# CTRL_MODULE_CORE register map
Vendor: Texas Instruments
Registers are 32-bit, access per field, reset 0x0 unless marked. A register's access mark holds for its fields unless they carry their own. Offsets are as the file gives them; [hi:lo] are bit positions; {n}, {i} and the like mark numbered series; 'fields as' and 'values as' point back to an identical list.

## CTRL_MODULE_CORE (part 5 of 11)
0xE78 CTRL_CORE_SRCOMP_SOUTH_SIDE ro — This register is related to the USB2_PHY2.
  [14:12] USB2PHY_CHG_DET_STATUS — Status of charger detection 0x0: Wait state 0x1: No contact 0x2: PS/2 0x3: Unknown error 0x4: Dedicated charger 0x5: HOST charger 0x6: PC 0x7: Interrupt
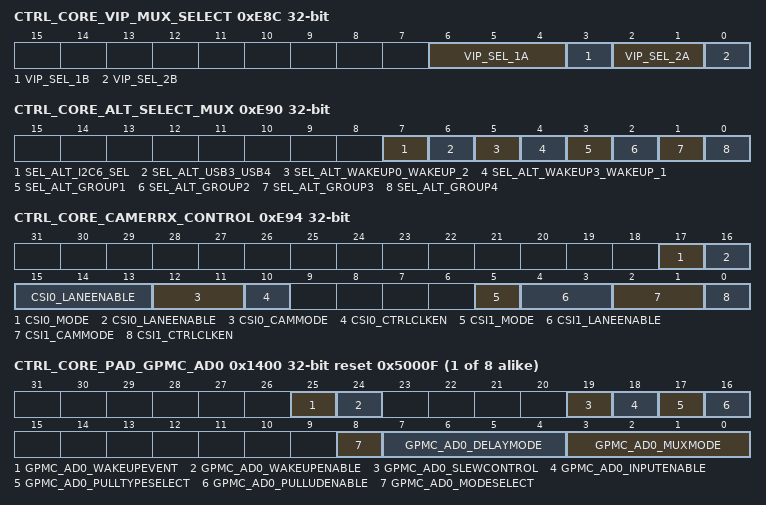
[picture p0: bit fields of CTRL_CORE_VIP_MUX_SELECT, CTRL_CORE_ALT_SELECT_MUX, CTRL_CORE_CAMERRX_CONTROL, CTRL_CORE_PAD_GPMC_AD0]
0xE8C CTRL_CORE_VIP_MUX_SELECT — Select the ports to be used with the VIP.
  [6:4] VIP_SEL_1A rw — Remaps the vin1a signals. 0x0: The vin1a signals are mapped to GROUP3A pads depending on the selected mux mode 0x1: The vin1a signals are mapped to GROUP5A pads depending on the selected mux mode 0x2: The vin1a signals are mapped to GROUP6A pads depending on the selected mux mode 0x3: The vin1a signals are mapped to GROUP4A pads depending on the selected mux mode 0x4-0x7: CAL Video Port signals are mapped to vin1a signals
  [3] VIP_SEL_1B rw — Remaps the vin1b signals. 0x0: The vin1b signals are mapped to GROUP4B pads depending on the selected mux mode 0x1: The vin1b signals are mapped to GROUP3B pads depending on the selected mux mode
  [2:1] VIP_SEL_2A rw — Remaps the vin2a signals. 0x0: The vin2a signals are mapped to GROUP2A pads depending on the selected mux mode 0x1: The vin2a signals are mapped to GROUP4A pads depending on the selected mux mode 0x2-0x3: CAL Video Port signals are mapped to vin2a signals
  [0] VIP_SEL_2B rw — Remaps the vin2b signals. 0x0: The vin2b signals are mapped to GROUP2B pads depending on the selected mux mode 0x1: The vin2b signals are mapped to GROUP3B pads depending on the selected mux mode
0xE90 CTRL_CORE_ALT_SELECT_MUX
  [7] SEL_ALT_I2C6_SEL rw — 0x0: The mcasp4_axr[0:1] pads have normal behavior. This means, the signal mapped to these pads depends on the MUXMODE field. 0x1: The i2c6_scl and i2c6_sda signals are mapped to the mcasp4_axr[0:1] pads, respectively. This setting overrides the MUXMODE setting.
  [6] SEL_ALT_USB3_USB4 rw — 0x0: The USB3 signals are mapped to USB_GROUP3 pads. 0x1: The USB3 signals are mapped to USB_GROUP4 pads.
  [5] SEL_ALT_WAKEUP0_WAKEUP_2 rw — 0x0: The gpio1_0 signal is on the Wakeup0 pad when MUXMODE = 0xE. 0x1: The sys_nirq2 signal is on the Wakeup0 pad when MUXMODE = 0xE.
  [4] SEL_ALT_WAKEUP3_WAKEUP_1 rw — 0x0: The gpio1_3 signal is on Wakeup3 pad when MUXMODE = 0xE. 0x1: The dcan2_rx signal is on the Wakeup3 pad when MUXMODE = 0xE.
  [3] SEL_ALT_GROUP1 rw — 0x0: GPIO function is selected on the pads from GROUP1 0x1: New function is selected on the pads from GROUP1 as described in
  [2] SEL_ALT_GROUP2 rw — Selects a signal as described in
  [1] SEL_ALT_GROUP3 rw — 0x0: GPIO function is selected on the pads from GROUP3 0x1: New function is selected on the pads from GROUP3 as described in
  [0] SEL_ALT_GROUP4 rw — Selects a signal as described in
0xE94 CTRL_CORE_CAMERRX_CONTROL — CSI2 PHY control register. Bit-fields CSI0_* control CSI2_PHY1. Bit-fields CSI1_* control CSI2_PHY2.
  [17] CSI0_MODE rw
  [16:13] CSI0_LANEENABLE rw — csi0 camera lane enable 0x0: Lane module disabled 0x1: Lane module enabled
  [12:11] CSI0_CAMMODE rw — csi0 camera mode 0x0: DPHY mode 0x1: Data/Strobe Transmission format 0x2: Data/Clock Transmission format 0x3: GPI mode
  [10] CSI0_CTRLCLKEN rw — csi0 camera clock enable control 0x0: Disable for CTRLCLK 0x1: Active high enable for CTRLCLK
  [5] CSI1_MODE rw
  [4:3] CSI1_LANEENABLE rw — csi1 camera lane enable 0x0: Lane module disabled 0x1: Lane module enabled
  [2:1] CSI1_CAMMODE rw — csi1 camera mode 0x0: DPHY mode 0x1: Data/Strobe Transmission format 0x2: Data/Clock Transmission format 0x3: GPI mode
  [0] CSI1_CTRLCLKEN rw — csi1 camera clock enable control 0x0: Disable for CTRLCLK 0x1: Active high enable for CTRLCLK
{0x1400+4i} CTRL_CORE_PAD_GPMC_AD{i} reset 0x5000F (i=0..7)
  [25] GPMC_AD{i}_WAKEUPEVENT ro
    0=NOWAKEUP (No wakeup event detected); 1=WAKEUP (Wakeup event detected)
  [24] GPMC_AD{i}_WAKEUPENABLE rw
    0=DISABLE (Wakeup is disabled); 1=ENABLE (Wakeup is enabled)
  [19] GPMC_AD{i}_SLEWCONTROL rw
    0=FAST_SLEW (Fast slew is selected); 1=SLOW_SLEW (Slow slew is selected)
  [18] GPMC_AD{i}_INPUTENABLE rw
    0=DISABLE (Receive mode is disabled); 1=ENABLE (Receive mode is enabled)
  [17] GPMC_AD{i}_PULLTYPESELECT rw
    0=PULL_DOWN (Pull Down is selected); 1=PULL_UP (Pull Up is selected)
  [16] GPMC_AD{i}_PULLUDENABLE rw
    0=ENABLE (Enables weak Pull Up/Down); 1=DISABLE (Disables weak Pull Up/Down)
  [8] GPMC_AD{i}_MODESELECT rw — Selects between the Default IO Timing Mode and a Virtual or Manual IO Timing Mode. Refer to the device Data Manual for definition of the required settings for a given mode of operation. When this bit is 0b1, a Virtual IO Timing Mode can be selected via the DELAYMODE field of this register, as described in, Virtual IO Timing Modes. Manual IO Timing Modes are selected via the procedure described in , Manual IO Timing Modes.
    0=MUX_MODE (Default IO Timing Mode is used); 1=DELAY_MODE (A Virtual or Manual IO Timing Mode is used)
  [7:4] GPMC_AD{i}_DELAYMODE rw — This bit field selects the Virtual Timing Mode used when the MODESELECT bit is set to 0b1. See, Virtual IO Timing Modes for details.
  [3:0] GPMC_AD{i}_MUXMODE rw
    0=GPMC_AD{i}; 2=VIN1A_D{i}; 3=VOUT3_D{i}; 14=GPIO1_{i+6}; 15=SYSBOOT{i}
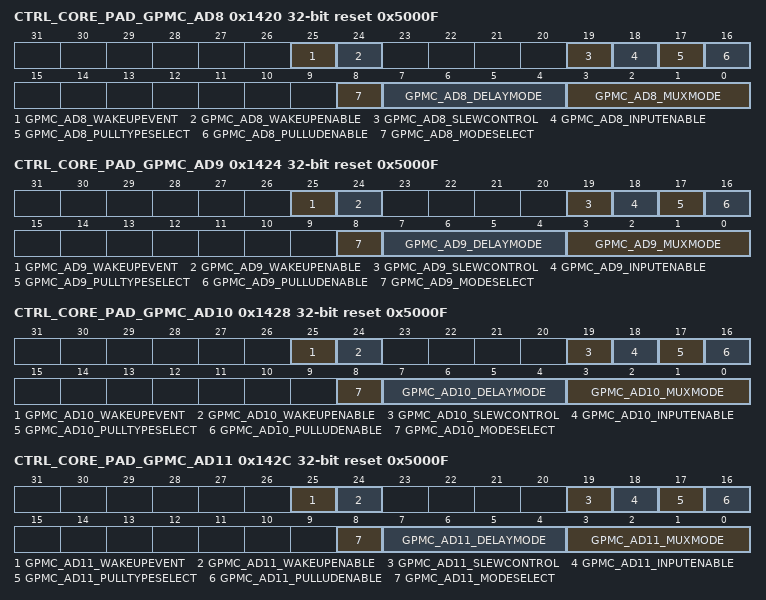
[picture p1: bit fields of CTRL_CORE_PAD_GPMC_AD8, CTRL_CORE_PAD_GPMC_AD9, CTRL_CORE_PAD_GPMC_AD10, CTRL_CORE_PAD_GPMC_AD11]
0x1420 CTRL_CORE_PAD_GPMC_AD8 reset 0x5000F
  [25] GPMC_AD8_WAKEUPEVENT ro
    values as CTRL_CORE_PAD_GPMC_AD0.GPMC_AD{i}_WAKEUPEVENT
  [24] GPMC_AD8_WAKEUPENABLE rw
    0=DISABLE (Wakeup is disabled); 1=ENABLE (Wakeup is enabled)
  [19] GPMC_AD8_SLEWCONTROL rw
    values as CTRL_CORE_PAD_GPMC_AD0.GPMC_AD{i}_SLEWCONTROL
  [18] GPMC_AD8_INPUTENABLE rw
    values as CTRL_CORE_PAD_GPMC_AD0.GPMC_AD{i}_INPUTENABLE
  [17] GPMC_AD8_PULLTYPESELECT rw
    values as CTRL_CORE_PAD_GPMC_AD0.GPMC_AD{i}_PULLTYPESELECT
  [16] GPMC_AD8_PULLUDENABLE rw
    values as CTRL_CORE_PAD_GPMC_AD0.GPMC_AD{i}_PULLUDENABLE
  [8] GPMC_AD8_MODESELECT rw — Selects between the Default IO Timing Mode and a Virtual or Manual IO Timing Mode. Refer to the device Data Manual for definition of the required settings for a given mode of operation. When this bit is 0b1, a Virtual IO Timing Mode can be selected via the DELAYMODE field of this register, as described in, Virtual IO Timing Modes. Manual IO Timing Modes are selected via the procedure described in , Manual IO Timing Modes.
    values as CTRL_CORE_PAD_GPMC_AD0.GPMC_AD{i}_MODESELECT
  [7:4] GPMC_AD8_DELAYMODE rw — This bit field selects the Virtual Timing Mode used when the MODESELECT bit is set to 0b1. See, Virtual IO Timing Modes for details.
  [3:0] GPMC_AD8_MUXMODE rw
    0=GPMC_AD8; 2=VIN1A_D8; 3=VOUT3_D8; 14=GPIO7_18; 15=SYSBOOT8
0x1424 CTRL_CORE_PAD_GPMC_AD9 reset 0x5000F
  [25] GPMC_AD9_WAKEUPEVENT ro
    values as CTRL_CORE_PAD_GPMC_AD0.GPMC_AD{i}_WAKEUPEVENT
  [24] GPMC_AD9_WAKEUPENABLE rw
    0=DISABLE (Wakeup is disabled); 1=ENABLE (Wakeup is enabled)
  [19] GPMC_AD9_SLEWCONTROL rw
    values as CTRL_CORE_PAD_GPMC_AD0.GPMC_AD{i}_SLEWCONTROL
  [18] GPMC_AD9_INPUTENABLE rw
    values as CTRL_CORE_PAD_GPMC_AD0.GPMC_AD{i}_INPUTENABLE
  [17] GPMC_AD9_PULLTYPESELECT rw
    values as CTRL_CORE_PAD_GPMC_AD0.GPMC_AD{i}_PULLTYPESELECT
  [16] GPMC_AD9_PULLUDENABLE rw
    values as CTRL_CORE_PAD_GPMC_AD0.GPMC_AD{i}_PULLUDENABLE
  [8] GPMC_AD9_MODESELECT rw — Selects between the Default IO Timing Mode and a Virtual or Manual IO Timing Mode. Refer to the device Data Manual for definition of the required settings for a given mode of operation. When this bit is 0b1, a Virtual IO Timing Mode can be selected via the DELAYMODE field of this register, as described in, Virtual IO Timing Modes. Manual IO Timing Modes are selected via the procedure described in , Manual IO Timing Modes.
    values as CTRL_CORE_PAD_GPMC_AD0.GPMC_AD{i}_MODESELECT
  [7:4] GPMC_AD9_DELAYMODE rw — This bit field selects the Virtual Timing Mode used when the MODESELECT bit is set to 0b1. See, Virtual IO Timing Modes for details.
  [3:0] GPMC_AD9_MUXMODE rw
    0=GPMC_AD9; 2=VIN1A_D9; 3=VOUT3_D9; 14=GPIO7_19; 15=SYSBOOT9
0x1428 CTRL_CORE_PAD_GPMC_AD10 reset 0x5000F
  [25] GPMC_AD10_WAKEUPEVENT ro
    values as CTRL_CORE_PAD_GPMC_AD0.GPMC_AD{i}_WAKEUPEVENT
  [24] GPMC_AD10_WAKEUPENABLE rw
    0=DISABLE (Wakeup is disabled); 1=ENABLE (Wakeup is enabled)
  [19] GPMC_AD10_SLEWCONTROL rw
    values as CTRL_CORE_PAD_GPMC_AD0.GPMC_AD{i}_SLEWCONTROL
  [18] GPMC_AD10_INPUTENABLE rw
    values as CTRL_CORE_PAD_GPMC_AD0.GPMC_AD{i}_INPUTENABLE
  [17] GPMC_AD10_PULLTYPESELECT rw
    values as CTRL_CORE_PAD_GPMC_AD0.GPMC_AD{i}_PULLTYPESELECT
  [16] GPMC_AD10_PULLUDENABLE rw
    values as CTRL_CORE_PAD_GPMC_AD0.GPMC_AD{i}_PULLUDENABLE
  [8] GPMC_AD10_MODESELECT rw — Selects between the Default IO Timing Mode and a Virtual or Manual IO Timing Mode. Refer to the device Data Manual for definition of the required settings for a given mode of operation. When this bit is 0b1, a Virtual IO Timing Mode can be selected via the DELAYMODE field of this register, as described in, Virtual IO Timing Modes. Manual IO Timing Modes are selected via the procedure described in , Manual IO Timing Modes.
    values as CTRL_CORE_PAD_GPMC_AD0.GPMC_AD{i}_MODESELECT
  [7:4] GPMC_AD10_DELAYMODE rw — This bit field selects the Virtual Timing Mode used when the MODESELECT bit is set to 0b1. See, Virtual IO Timing Modes for details.
  [3:0] GPMC_AD10_MUXMODE rw
    0=GPMC_AD10; 2=VIN1A_D10; 3=VOUT3_D10; 14=GPIO7_28; 15=SYSBOOT10
0x142C CTRL_CORE_PAD_GPMC_AD11 reset 0x5000F
  [25] GPMC_AD11_WAKEUPEVENT ro
    values as CTRL_CORE_PAD_GPMC_AD0.GPMC_AD{i}_WAKEUPEVENT
  [24] GPMC_AD11_WAKEUPENABLE rw
    0=DISABLE (Wakeup is disabled); 1=ENABLE (Wakeup is enabled)
  [19] GPMC_AD11_SLEWCONTROL rw
    values as CTRL_CORE_PAD_GPMC_AD0.GPMC_AD{i}_SLEWCONTROL
  [18] GPMC_AD11_INPUTENABLE rw
    values as CTRL_CORE_PAD_GPMC_AD0.GPMC_AD{i}_INPUTENABLE
  [17] GPMC_AD11_PULLTYPESELECT rw
    values as CTRL_CORE_PAD_GPMC_AD0.GPMC_AD{i}_PULLTYPESELECT
  [16] GPMC_AD11_PULLUDENABLE rw
    values as CTRL_CORE_PAD_GPMC_AD0.GPMC_AD{i}_PULLUDENABLE
  [8] GPMC_AD11_MODESELECT rw — Selects between the Default IO Timing Mode and a Virtual or Manual IO Timing Mode. Refer to the device Data Manual for definition of the required settings for a given mode of operation. When this bit is 0b1, a Virtual IO Timing Mode can be selected via the DELAYMODE field of this register, as described in, Virtual IO Timing Modes. Manual IO Timing Modes are selected via the procedure described in , Manual IO Timing Modes.
    values as CTRL_CORE_PAD_GPMC_AD0.GPMC_AD{i}_MODESELECT
  [7:4] GPMC_AD11_DELAYMODE rw — This bit field selects the Virtual Timing Mode used when the MODESELECT bit is set to 0b1. See, Virtual IO Timing Modes for details.
  [3:0] GPMC_AD11_MUXMODE rw
    0=GPMC_AD11; 2=VIN1A_D11; 3=VOUT3_D11; 14=GPIO7_29; 15=SYSBOOT11
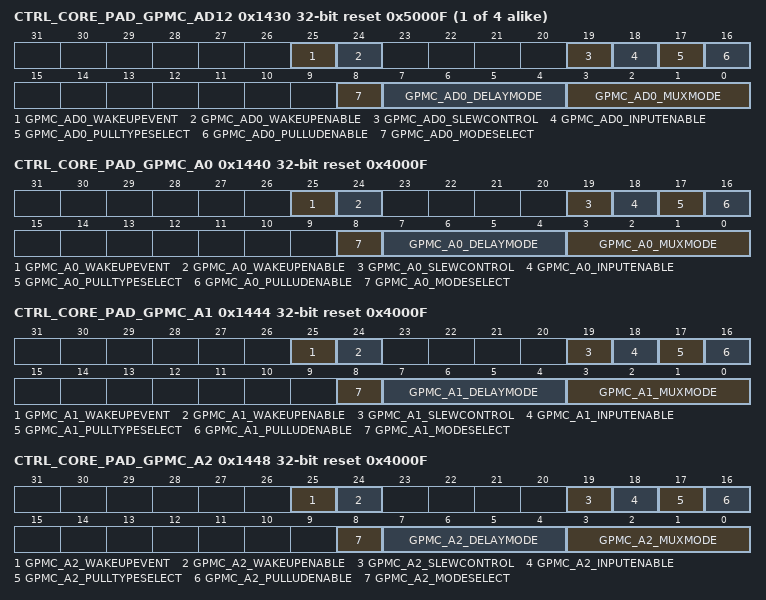
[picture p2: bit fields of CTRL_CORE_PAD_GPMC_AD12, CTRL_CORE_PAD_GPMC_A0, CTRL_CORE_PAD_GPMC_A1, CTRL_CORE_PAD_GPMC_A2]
{0x1400+4i} CTRL_CORE_PAD_GPMC_AD{i} reset 0x5000F (i=12..15)
  fields as CTRL_CORE_PAD_GPMC_AD0
0x1440 CTRL_CORE_PAD_GPMC_A0 reset 0x4000F
  [25] GPMC_A0_WAKEUPEVENT ro
    values as CTRL_CORE_PAD_GPMC_AD0.GPMC_AD{i}_WAKEUPEVENT
  [24] GPMC_A0_WAKEUPENABLE rw
    0=DISABLE (Wakeup is disabled); 1=ENABLE (Wakeup is enabled)
  [19] GPMC_A0_SLEWCONTROL rw
    values as CTRL_CORE_PAD_GPMC_AD0.GPMC_AD{i}_SLEWCONTROL
  [18] GPMC_A0_INPUTENABLE rw
    values as CTRL_CORE_PAD_GPMC_AD0.GPMC_AD{i}_INPUTENABLE
  [17] GPMC_A0_PULLTYPESELECT rw
    values as CTRL_CORE_PAD_GPMC_AD0.GPMC_AD{i}_PULLTYPESELECT
  [16] GPMC_A0_PULLUDENABLE rw
    values as CTRL_CORE_PAD_GPMC_AD0.GPMC_AD{i}_PULLUDENABLE
  [8] GPMC_A0_MODESELECT rw — Selects between the Default IO Timing Mode and a Virtual or Manual IO Timing Mode. Refer to the device Data Manual for definition of the required settings for a given mode of operation. When this bit is 0b1, a Virtual IO Timing Mode can be selected via the DELAYMODE field of this register, as described in, Virtual IO Timing Modes. Manual IO Timing Modes are selected via the procedure described in , Manual IO Timing Modes.
    values as CTRL_CORE_PAD_GPMC_AD0.GPMC_AD{i}_MODESELECT
  [7:4] GPMC_A0_DELAYMODE rw — This bit field selects the Virtual Timing Mode used when the MODESELECT bit is set to 0b1. See, Virtual IO Timing Modes for details.
  [3:0] GPMC_A0_MUXMODE rw
    0=GPMC_A0; 2=VIN1A_D16; 3=VOUT3_D16; 4=VIN2A_D0 VIN1A_D0; 6=VIN1B_D0; 7=I2C4_SCL; 8=UART5_RXD; 14=GPIO7_3 GPMC_A26 GPMC_A16; 15=DRIVER OFF
0x1444 CTRL_CORE_PAD_GPMC_A1 reset 0x4000F
  [25] GPMC_A1_WAKEUPEVENT ro
    values as CTRL_CORE_PAD_GPMC_AD0.GPMC_AD{i}_WAKEUPEVENT
  [24] GPMC_A1_WAKEUPENABLE rw
    0=DISABLE (Wakeup is disabled); 1=ENABLE (Wakeup is enabled)
  [19] GPMC_A1_SLEWCONTROL rw
    values as CTRL_CORE_PAD_GPMC_AD0.GPMC_AD{i}_SLEWCONTROL
  [18] GPMC_A1_INPUTENABLE rw
    values as CTRL_CORE_PAD_GPMC_AD0.GPMC_AD{i}_INPUTENABLE
  [17] GPMC_A1_PULLTYPESELECT rw
    values as CTRL_CORE_PAD_GPMC_AD0.GPMC_AD{i}_PULLTYPESELECT
  [16] GPMC_A1_PULLUDENABLE rw
    values as CTRL_CORE_PAD_GPMC_AD0.GPMC_AD{i}_PULLUDENABLE
  [8] GPMC_A1_MODESELECT rw — Selects between the Default IO Timing Mode and a Virtual or Manual IO Timing Mode. Refer to the device Data Manual for definition of the required settings for a given mode of operation. When this bit is 0b1, a Virtual IO Timing Mode can be selected via the DELAYMODE field of this register, as described in, Virtual IO Timing Modes. Manual IO Timing Modes are selected via the procedure described in , Manual IO Timing Modes.
    values as CTRL_CORE_PAD_GPMC_AD0.GPMC_AD{i}_MODESELECT
  [7:4] GPMC_A1_DELAYMODE rw — This bit field selects the Virtual Timing Mode used when the MODESELECT bit is set to 0b1. See, Virtual IO Timing Modes for details.
  [3:0] GPMC_A1_MUXMODE rw
    0=GPMC_A1; 2=VIN1A_D17; 3=VOUT3_D17; 4=VIN2A_D1 VIN1A_D1; 6=VIN1B_D1; 7=I2C4_SDA; 8=UART5_TXD; 14=GPIO7_4; 15=DRIVER OFF
0x1448 CTRL_CORE_PAD_GPMC_A2 reset 0x4000F
  [25] GPMC_A2_WAKEUPEVENT ro
    values as CTRL_CORE_PAD_GPMC_AD0.GPMC_AD{i}_WAKEUPEVENT
  [24] GPMC_A2_WAKEUPENABLE rw
    0=DISABLE (Wakeup is disabled); 1=ENABLE (Wakeup is enabled)
  [19] GPMC_A2_SLEWCONTROL rw
    values as CTRL_CORE_PAD_GPMC_AD0.GPMC_AD{i}_SLEWCONTROL
  [18] GPMC_A2_INPUTENABLE rw
    values as CTRL_CORE_PAD_GPMC_AD0.GPMC_AD{i}_INPUTENABLE
  [17] GPMC_A2_PULLTYPESELECT rw
    values as CTRL_CORE_PAD_GPMC_AD0.GPMC_AD{i}_PULLTYPESELECT
  [16] GPMC_A2_PULLUDENABLE rw
    values as CTRL_CORE_PAD_GPMC_AD0.GPMC_AD{i}_PULLUDENABLE
  [8] GPMC_A2_MODESELECT rw — Selects between the Default IO Timing Mode and a Virtual or Manual IO Timing Mode. Refer to the device Data Manual for definition of the required settings for a given mode of operation. When this bit is 0b1, a Virtual IO Timing Mode can be selected via the DELAYMODE field of this register, as described in, Virtual IO Timing Modes. Manual IO Timing Modes are selected via the procedure described in , Manual IO Timing Modes.
    values as CTRL_CORE_PAD_GPMC_AD0.GPMC_AD{i}_MODESELECT
  [7:4] GPMC_A2_DELAYMODE rw — This bit field selects the Virtual Timing Mode used when the MODESELECT bit is set to 0b1. See, Virtual IO Timing Modes for details.
  [3:0] GPMC_A2_MUXMODE rw
    0=GPMC_A2; 2=VIN1A_D18; 3=VOUT3_D18; 4=VIN2A_D2 VIN1A_D2; 6=VIN1B_D2; 7=UART7_RXD; 8=UART5_CTSN; 14=GPIO7_5; 15=DRIVER OFF
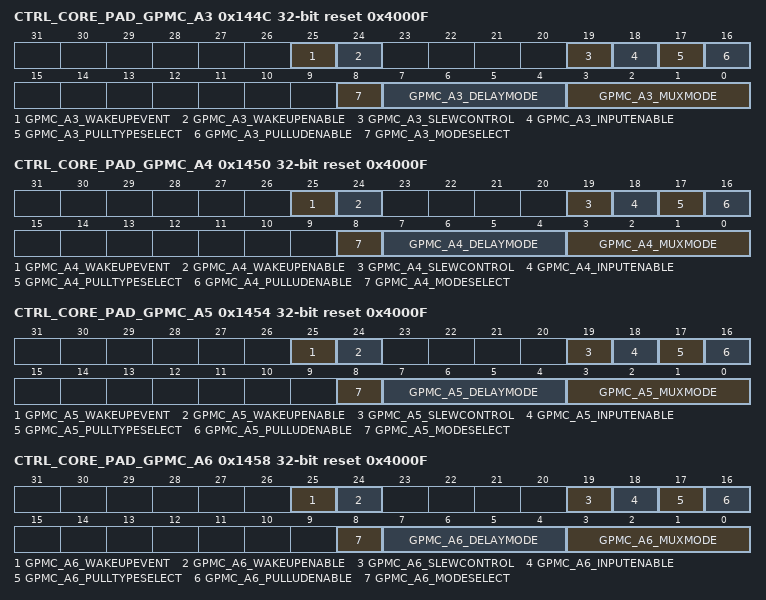
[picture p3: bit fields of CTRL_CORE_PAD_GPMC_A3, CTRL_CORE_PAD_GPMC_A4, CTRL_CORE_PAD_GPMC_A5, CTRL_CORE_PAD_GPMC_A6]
0x144C CTRL_CORE_PAD_GPMC_A3 reset 0x4000F
  [25] GPMC_A3_WAKEUPEVENT ro
    values as CTRL_CORE_PAD_GPMC_AD0.GPMC_AD{i}_WAKEUPEVENT
  [24] GPMC_A3_WAKEUPENABLE rw
    0=DISABLE (Wakeup is disabled); 1=ENABLE (Wakeup is enabled)
  [19] GPMC_A3_SLEWCONTROL rw
    values as CTRL_CORE_PAD_GPMC_AD0.GPMC_AD{i}_SLEWCONTROL
  [18] GPMC_A3_INPUTENABLE rw
    values as CTRL_CORE_PAD_GPMC_AD0.GPMC_AD{i}_INPUTENABLE
  [17] GPMC_A3_PULLTYPESELECT rw
    values as CTRL_CORE_PAD_GPMC_AD0.GPMC_AD{i}_PULLTYPESELECT
  [16] GPMC_A3_PULLUDENABLE rw
    values as CTRL_CORE_PAD_GPMC_AD0.GPMC_AD{i}_PULLUDENABLE
  [8] GPMC_A3_MODESELECT rw — Selects between the Default IO Timing Mode and a Virtual or Manual IO Timing Mode. Refer to the device Data Manual for definition of the required settings for a given mode of operation. When this bit is 0b1, a Virtual IO Timing Mode can be selected via the DELAYMODE field of this register, as described in, Virtual IO Timing Modes. Manual IO Timing Modes are selected via the procedure described in , Manual IO Timing Modes.
    values as CTRL_CORE_PAD_GPMC_AD0.GPMC_AD{i}_MODESELECT
  [7:4] GPMC_A3_DELAYMODE rw — This bit field selects the Virtual Timing Mode used when the MODESELECT bit is set to 0b1. See, Virtual IO Timing Modes for details.
  [3:0] GPMC_A3_MUXMODE rw
    0=GPMC_A3; 1=QSPI1_CS2; 2=VIN1A_D19; 3=VOUT3_D19; 4=VIN2A_D3 VIN1A_D3; 6=VIN1B_D3; 7=UART7_TXD; 8=UART5_RTSN; 14=GPIO7_6; 15=DRIVER OFF
0x1450 CTRL_CORE_PAD_GPMC_A4 reset 0x4000F
  [25] GPMC_A4_WAKEUPEVENT ro
    values as CTRL_CORE_PAD_GPMC_AD0.GPMC_AD{i}_WAKEUPEVENT
  [24] GPMC_A4_WAKEUPENABLE rw
    0=DISABLE (Wakeup is disabled); 1=ENABLE (Wakeup is enabled)
  [19] GPMC_A4_SLEWCONTROL rw
    values as CTRL_CORE_PAD_GPMC_AD0.GPMC_AD{i}_SLEWCONTROL
  [18] GPMC_A4_INPUTENABLE rw
    values as CTRL_CORE_PAD_GPMC_AD0.GPMC_AD{i}_INPUTENABLE
  [17] GPMC_A4_PULLTYPESELECT rw
    values as CTRL_CORE_PAD_GPMC_AD0.GPMC_AD{i}_PULLTYPESELECT
  [16] GPMC_A4_PULLUDENABLE rw
    values as CTRL_CORE_PAD_GPMC_AD0.GPMC_AD{i}_PULLUDENABLE
  [8] GPMC_A4_MODESELECT rw — Selects between the Default IO Timing Mode and a Virtual or Manual IO Timing Mode. Refer to the device Data Manual for definition of the required settings for a given mode of operation. When this bit is 0b1, a Virtual IO Timing Mode can be selected via the DELAYMODE field of this register, as described in, Virtual IO Timing Modes. Manual IO Timing Modes are selected via the procedure described in , Manual IO Timing Modes.
    values as CTRL_CORE_PAD_GPMC_AD0.GPMC_AD{i}_MODESELECT
  [7:4] GPMC_A4_DELAYMODE rw — This bit field selects the Virtual Timing Mode used when the MODESELECT bit is set to 0b1. See, Virtual IO Timing Modes for details.
  [3:0] GPMC_A4_MUXMODE rw
    0=GPMC_A4; 1=QSPI1_CS3; 2=VIN1A_D20; 3=VOUT3_D20; 4=VIN2A_D4 VIN1A_D4; 6=VIN1B_D4; 7=I2C5_SCL; 8=UART6_RXD; 14=GPIO1_26; 15=DRIVER OFF
0x1454 CTRL_CORE_PAD_GPMC_A5 reset 0x4000F
  [25] GPMC_A5_WAKEUPEVENT ro
    values as CTRL_CORE_PAD_GPMC_AD0.GPMC_AD{i}_WAKEUPEVENT
  [24] GPMC_A5_WAKEUPENABLE rw
    0=DISABLE (Wakeup is disabled); 1=ENABLE (Wakeup is enabled)
  [19] GPMC_A5_SLEWCONTROL rw
    values as CTRL_CORE_PAD_GPMC_AD0.GPMC_AD{i}_SLEWCONTROL
  [18] GPMC_A5_INPUTENABLE rw
    values as CTRL_CORE_PAD_GPMC_AD0.GPMC_AD{i}_INPUTENABLE
  [17] GPMC_A5_PULLTYPESELECT rw
    values as CTRL_CORE_PAD_GPMC_AD0.GPMC_AD{i}_PULLTYPESELECT
  [16] GPMC_A5_PULLUDENABLE rw
    values as CTRL_CORE_PAD_GPMC_AD0.GPMC_AD{i}_PULLUDENABLE
  [8] GPMC_A5_MODESELECT rw — Selects between the Default IO Timing Mode and a Virtual or Manual IO Timing Mode. Refer to the device Data Manual for definition of the required settings for a given mode of operation. When this bit is 0b1, a Virtual IO Timing Mode can be selected via the DELAYMODE field of this register, as described in, Virtual IO Timing Modes. Manual IO Timing Modes are selected via the procedure described in , Manual IO Timing Modes.
    values as CTRL_CORE_PAD_GPMC_AD0.GPMC_AD{i}_MODESELECT
  [7:4] GPMC_A5_DELAYMODE rw — This bit field selects the Virtual Timing Mode used when the MODESELECT bit is set to 0b1. See, Virtual IO Timing Modes for details.
  [3:0] GPMC_A5_MUXMODE rw
    0=GPMC_A5; 2=VIN1A_D21; 3=VOUT3_D21; 4=VIN2A_D5 VIN1A_D5; 6=VIN1B_D5; 7=I2C5_SDA; 8=UART6_TXD; 14=GPIO1_27; 15=DRIVER OFF
0x1458 CTRL_CORE_PAD_GPMC_A6 reset 0x4000F
  [25] GPMC_A6_WAKEUPEVENT ro
    values as CTRL_CORE_PAD_GPMC_AD0.GPMC_AD{i}_WAKEUPEVENT
  [24] GPMC_A6_WAKEUPENABLE rw
    0=DISABLE (Wakeup is disabled); 1=ENABLE (Wakeup is enabled)
  [19] GPMC_A6_SLEWCONTROL rw
    values as CTRL_CORE_PAD_GPMC_AD0.GPMC_AD{i}_SLEWCONTROL
  [18] GPMC_A6_INPUTENABLE rw
    values as CTRL_CORE_PAD_GPMC_AD0.GPMC_AD{i}_INPUTENABLE
  [17] GPMC_A6_PULLTYPESELECT rw
    values as CTRL_CORE_PAD_GPMC_AD0.GPMC_AD{i}_PULLTYPESELECT
  [16] GPMC_A6_PULLUDENABLE rw
    values as CTRL_CORE_PAD_GPMC_AD0.GPMC_AD{i}_PULLUDENABLE
  [8] GPMC_A6_MODESELECT rw — Selects between the Default IO Timing Mode and a Virtual or Manual IO Timing Mode. Refer to the device Data Manual for definition of the required settings for a given mode of operation. When this bit is 0b1, a Virtual IO Timing Mode can be selected via the DELAYMODE field of this register, as described in, Virtual IO Timing Modes. Manual IO Timing Modes are selected via the procedure described in , Manual IO Timing Modes.
    values as CTRL_CORE_PAD_GPMC_AD0.GPMC_AD{i}_MODESELECT
  [7:4] GPMC_A6_DELAYMODE rw — This bit field selects the Virtual Timing Mode used when the MODESELECT bit is set to 0b1. See, Virtual IO Timing Modes for details.
  [3:0] GPMC_A6_MUXMODE rw
    0=GPMC_A6; 2=VIN1A_D22; 3=VOUT3_D22; 4=VIN2A_D6 VIN1A_D6; 6=VIN1B_D6; 7=UART8_RXD; 8=UART6_CTSN; 14=GPIO1_28; 15=DRIVER OFF
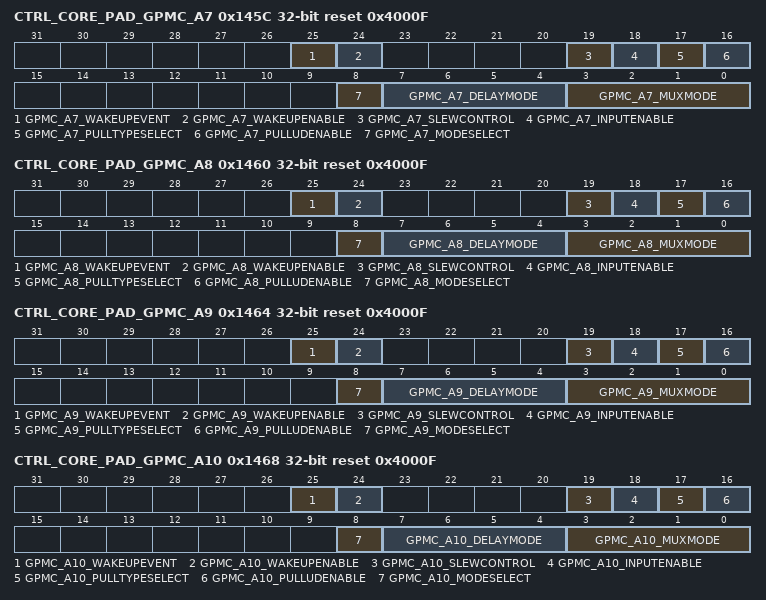
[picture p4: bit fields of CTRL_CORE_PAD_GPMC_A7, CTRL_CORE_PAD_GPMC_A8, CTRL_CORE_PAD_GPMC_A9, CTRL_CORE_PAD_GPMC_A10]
0x145C CTRL_CORE_PAD_GPMC_A7 reset 0x4000F
  [25] GPMC_A7_WAKEUPEVENT ro
    values as CTRL_CORE_PAD_GPMC_AD0.GPMC_AD{i}_WAKEUPEVENT
  [24] GPMC_A7_WAKEUPENABLE rw
    0=DISABLE (Wakeup is disabled); 1=ENABLE (Wakeup is enabled)
  [19] GPMC_A7_SLEWCONTROL rw
    values as CTRL_CORE_PAD_GPMC_AD0.GPMC_AD{i}_SLEWCONTROL
  [18] GPMC_A7_INPUTENABLE rw
    values as CTRL_CORE_PAD_GPMC_AD0.GPMC_AD{i}_INPUTENABLE
  [17] GPMC_A7_PULLTYPESELECT rw
    values as CTRL_CORE_PAD_GPMC_AD0.GPMC_AD{i}_PULLTYPESELECT
  [16] GPMC_A7_PULLUDENABLE rw
    values as CTRL_CORE_PAD_GPMC_AD0.GPMC_AD{i}_PULLUDENABLE
  [8] GPMC_A7_MODESELECT rw — Selects between the Default IO Timing Mode and a Virtual or Manual IO Timing Mode. Refer to the device Data Manual for definition of the required settings for a given mode of operation. When this bit is 0b1, a Virtual IO Timing Mode can be selected via the DELAYMODE field of this register, as described in, Virtual IO Timing Modes. Manual IO Timing Modes are selected via the procedure described in , Manual IO Timing Modes.
    values as CTRL_CORE_PAD_GPMC_AD0.GPMC_AD{i}_MODESELECT
  [7:4] GPMC_A7_DELAYMODE rw — This bit field selects the Virtual Timing Mode used when the MODESELECT bit is set to 0b1. See, Virtual IO Timing Modes for details.
  [3:0] GPMC_A7_MUXMODE rw
    0=GPMC_A7; 2=VIN1A_D23; 3=VOUT3_D23; 4=VIN2A_D7 VIN1A_D7; 6=VIN1B_D7; 7=UART8_TXD; 8=UART6_RTSN; 14=GPIO1_29; 15=DRIVER OFF
0x1460 CTRL_CORE_PAD_GPMC_A8 reset 0x4000F
  [25] GPMC_A8_WAKEUPEVENT ro
    values as CTRL_CORE_PAD_GPMC_AD0.GPMC_AD{i}_WAKEUPEVENT
  [24] GPMC_A8_WAKEUPENABLE rw
    0=DISABLE (Wakeup is disabled); 1=ENABLE (Wakeup is enabled)
  [19] GPMC_A8_SLEWCONTROL rw
    values as CTRL_CORE_PAD_GPMC_AD0.GPMC_AD{i}_SLEWCONTROL
  [18] GPMC_A8_INPUTENABLE rw
    values as CTRL_CORE_PAD_GPMC_AD0.GPMC_AD{i}_INPUTENABLE
  [17] GPMC_A8_PULLTYPESELECT rw
    values as CTRL_CORE_PAD_GPMC_AD0.GPMC_AD{i}_PULLTYPESELECT
  [16] GPMC_A8_PULLUDENABLE rw
    values as CTRL_CORE_PAD_GPMC_AD0.GPMC_AD{i}_PULLUDENABLE
  [8] GPMC_A8_MODESELECT rw — Selects between the Default IO Timing Mode and a Virtual or Manual IO Timing Mode. Refer to the device Data Manual for definition of the required settings for a given mode of operation. When this bit is 0b1, a Virtual IO Timing Mode can be selected via the DELAYMODE field of this register, as described in, Virtual IO Timing Modes. Manual IO Timing Modes are selected via the procedure described in , Manual IO Timing Modes.
    values as CTRL_CORE_PAD_GPMC_AD0.GPMC_AD{i}_MODESELECT
  [7:4] GPMC_A8_DELAYMODE rw — This bit field selects the Virtual Timing Mode used when the MODESELECT bit is set to 0b1. See, Virtual IO Timing Modes for details.
  [3:0] GPMC_A8_MUXMODE rw
    0=GPMC_A8; 2=VIN1A_HSYNC0; 3=VOUT3_HSYNC; 6=VIN1B_HSYNC1; 7=TIMER12; 8=SPI4_SCLK; 14=GPIO1_30; 15=DRIVER OFF
0x1464 CTRL_CORE_PAD_GPMC_A9 reset 0x4000F
  [25] GPMC_A9_WAKEUPEVENT ro
    values as CTRL_CORE_PAD_GPMC_AD0.GPMC_AD{i}_WAKEUPEVENT
  [24] GPMC_A9_WAKEUPENABLE rw
    0=DISABLE (Wakeup is disabled); 1=ENABLE (Wakeup is enabled)
  [19] GPMC_A9_SLEWCONTROL rw
    values as CTRL_CORE_PAD_GPMC_AD0.GPMC_AD{i}_SLEWCONTROL
  [18] GPMC_A9_INPUTENABLE rw
    values as CTRL_CORE_PAD_GPMC_AD0.GPMC_AD{i}_INPUTENABLE
  [17] GPMC_A9_PULLTYPESELECT rw
    values as CTRL_CORE_PAD_GPMC_AD0.GPMC_AD{i}_PULLTYPESELECT
  [16] GPMC_A9_PULLUDENABLE rw
    values as CTRL_CORE_PAD_GPMC_AD0.GPMC_AD{i}_PULLUDENABLE
  [8] GPMC_A9_MODESELECT rw — Selects between the Default IO Timing Mode and a Virtual or Manual IO Timing Mode. Refer to the device Data Manual for definition of the required settings for a given mode of operation. When this bit is 0b1, a Virtual IO Timing Mode can be selected via the DELAYMODE field of this register, as described in, Virtual IO Timing Modes. Manual IO Timing Modes are selected via the procedure described in , Manual IO Timing Modes.
    values as CTRL_CORE_PAD_GPMC_AD0.GPMC_AD{i}_MODESELECT
  [7:4] GPMC_A9_DELAYMODE rw — This bit field selects the Virtual Timing Mode used when the MODESELECT bit is set to 0b1. See, Virtual IO Timing Modes for details.
  [3:0] GPMC_A9_MUXMODE rw
    0=GPMC_A9; 2=VIN1A_VSYNC0; 3=VOUT3_VSYNC; 6=VIN1B_VSYNC1; 7=TIMER11; 8=SPI4_D1; 14=GPIO1_31; 15=DRIVER OFF
0x1468 CTRL_CORE_PAD_GPMC_A10 reset 0x4000F
  [25] GPMC_A10_WAKEUPEVENT ro
    values as CTRL_CORE_PAD_GPMC_AD0.GPMC_AD{i}_WAKEUPEVENT
  [24] GPMC_A10_WAKEUPENABLE rw
    0=DISABLE (Wakeup is disabled); 1=ENABLE (Wakeup is enabled)
  [19] GPMC_A10_SLEWCONTROL rw
    values as CTRL_CORE_PAD_GPMC_AD0.GPMC_AD{i}_SLEWCONTROL
  [18] GPMC_A10_INPUTENABLE rw
    values as CTRL_CORE_PAD_GPMC_AD0.GPMC_AD{i}_INPUTENABLE
  [17] GPMC_A10_PULLTYPESELECT rw
    values as CTRL_CORE_PAD_GPMC_AD0.GPMC_AD{i}_PULLTYPESELECT
  [16] GPMC_A10_PULLUDENABLE rw
    values as CTRL_CORE_PAD_GPMC_AD0.GPMC_AD{i}_PULLUDENABLE
  [8] GPMC_A10_MODESELECT rw — Selects between the Default IO Timing Mode and a Virtual or Manual IO Timing Mode. Refer to the device Data Manual for definition of the required settings for a given mode of operation. When this bit is 0b1, a Virtual IO Timing Mode can be selected via the DELAYMODE field of this register, as described in, Virtual IO Timing Modes. Manual IO Timing Modes are selected via the procedure described in , Manual IO Timing Modes.
    values as CTRL_CORE_PAD_GPMC_AD0.GPMC_AD{i}_MODESELECT
  [7:4] GPMC_A10_DELAYMODE rw — This bit field selects the Virtual Timing Mode used when the MODESELECT bit is set to 0b1. See, Virtual IO Timing Modes for details.
  [3:0] GPMC_A10_MUXMODE rw
    0=GPMC_A10; 2=VIN1A_DE0; 3=VOUT3_DE; 6=VIN1B_CLK1; 7=TIMER10; 8=SPI4_D0; 14=GPIO2_0; 15=DRIVER OFF
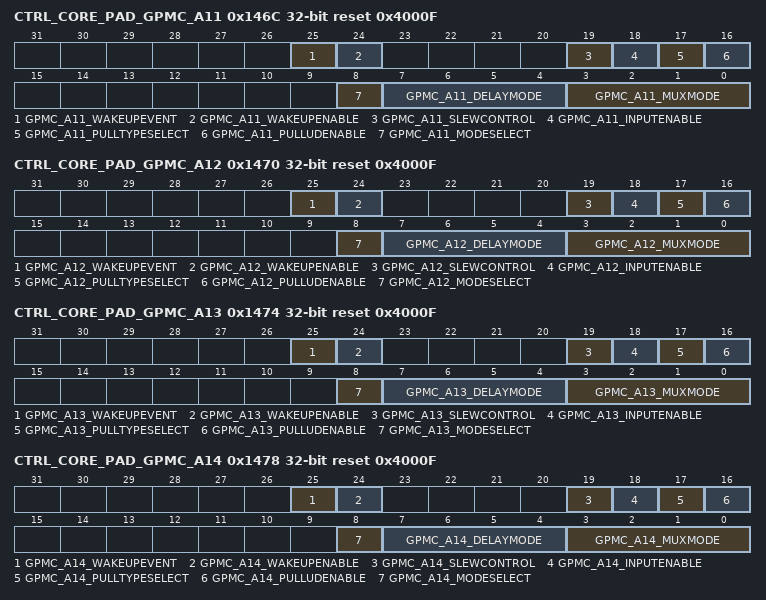
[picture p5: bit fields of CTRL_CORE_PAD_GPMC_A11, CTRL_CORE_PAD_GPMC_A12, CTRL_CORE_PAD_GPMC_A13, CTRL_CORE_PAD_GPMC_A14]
0x146C CTRL_CORE_PAD_GPMC_A11 reset 0x4000F
  [25] GPMC_A11_WAKEUPEVENT ro
    values as CTRL_CORE_PAD_GPMC_AD0.GPMC_AD{i}_WAKEUPEVENT
  [24] GPMC_A11_WAKEUPENABLE rw
    0=DISABLE (Wakeup is disabled); 1=ENABLE (Wakeup is enabled)
  [19] GPMC_A11_SLEWCONTROL rw
    values as CTRL_CORE_PAD_GPMC_AD0.GPMC_AD{i}_SLEWCONTROL
  [18] GPMC_A11_INPUTENABLE rw
    values as CTRL_CORE_PAD_GPMC_AD0.GPMC_AD{i}_INPUTENABLE
  [17] GPMC_A11_PULLTYPESELECT rw
    values as CTRL_CORE_PAD_GPMC_AD0.GPMC_AD{i}_PULLTYPESELECT
  [16] GPMC_A11_PULLUDENABLE rw
    values as CTRL_CORE_PAD_GPMC_AD0.GPMC_AD{i}_PULLUDENABLE
  [8] GPMC_A11_MODESELECT rw — Selects between the Default IO Timing Mode and a Virtual or Manual IO Timing Mode. Refer to the device Data Manual for definition of the required settings for a given mode of operation. When this bit is 0b1, a Virtual IO Timing Mode can be selected via the DELAYMODE field of this register, as described in, Virtual IO Timing Modes. Manual IO Timing Modes are selected via the procedure described in , Manual IO Timing Modes.
    values as CTRL_CORE_PAD_GPMC_AD0.GPMC_AD{i}_MODESELECT
  [7:4] GPMC_A11_DELAYMODE rw — This bit field selects the Virtual Timing Mode used when the MODESELECT bit is set to 0b1. See, Virtual IO Timing Modes for details.
  [3:0] GPMC_A11_MUXMODE rw
    0=GPMC_A11; 2=VIN1A_FLD0; 3=VOUT3_FLD; 4=VIN2A_FLD0 VIN1A_FLD0; 6=VIN1B_DE1; 7=TIMER9; 8=SPI4_CS0; 14=GPIO2_1; 15=DRIVER OFF
0x1470 CTRL_CORE_PAD_GPMC_A12 reset 0x4000F
  [25] GPMC_A12_WAKEUPEVENT ro
    values as CTRL_CORE_PAD_GPMC_AD0.GPMC_AD{i}_WAKEUPEVENT
  [24] GPMC_A12_WAKEUPENABLE rw
    0=DISABLE (Wakeup is disabled); 1=ENABLE (Wakeup is enabled)
  [19] GPMC_A12_SLEWCONTROL rw
    values as CTRL_CORE_PAD_GPMC_AD0.GPMC_AD{i}_SLEWCONTROL
  [18] GPMC_A12_INPUTENABLE rw
    values as CTRL_CORE_PAD_GPMC_AD0.GPMC_AD{i}_INPUTENABLE
  [17] GPMC_A12_PULLTYPESELECT rw
    values as CTRL_CORE_PAD_GPMC_AD0.GPMC_AD{i}_PULLTYPESELECT
  [16] GPMC_A12_PULLUDENABLE rw
    values as CTRL_CORE_PAD_GPMC_AD0.GPMC_AD{i}_PULLUDENABLE
  [8] GPMC_A12_MODESELECT rw — Selects between the Default IO Timing Mode and a Virtual or Manual IO Timing Mode. Refer to the device Data Manual for definition of the required settings for a given mode of operation. When this bit is 0b1, a Virtual IO Timing Mode can be selected via the DELAYMODE field of this register, as described in, Virtual IO Timing Modes. Manual IO Timing Modes are selected via the procedure described in , Manual IO Timing Modes.
    values as CTRL_CORE_PAD_GPMC_AD0.GPMC_AD{i}_MODESELECT
  [7:4] GPMC_A12_DELAYMODE rw — This bit field selects the Virtual Timing Mode used when the MODESELECT bit is set to 0b1. See, Virtual IO Timing Modes for details.
  [3:0] GPMC_A12_MUXMODE rw
    0=GPMC_A12; 4=VIN2A_CLK0 VIN1A_CLK0; 5=GPMC_A0; 6=VIN1B_FLD1; 7=TIMER8; 8=SPI4_CS1; 9=DMA_EVT1; 14=GPIO2_2; 15=DRIVER OFF
0x1474 CTRL_CORE_PAD_GPMC_A13 reset 0x4000F
  [25] GPMC_A13_WAKEUPEVENT ro
    values as CTRL_CORE_PAD_GPMC_AD0.GPMC_AD{i}_WAKEUPEVENT
  [24] GPMC_A13_WAKEUPENABLE rw
    0=DISABLE (Wakeup is disabled); 1=ENABLE (Wakeup is enabled)
  [19] GPMC_A13_SLEWCONTROL rw
    values as CTRL_CORE_PAD_GPMC_AD0.GPMC_AD{i}_SLEWCONTROL
  [18] GPMC_A13_INPUTENABLE rw
    values as CTRL_CORE_PAD_GPMC_AD0.GPMC_AD{i}_INPUTENABLE
  [17] GPMC_A13_PULLTYPESELECT rw
    values as CTRL_CORE_PAD_GPMC_AD0.GPMC_AD{i}_PULLTYPESELECT
  [16] GPMC_A13_PULLUDENABLE rw
    values as CTRL_CORE_PAD_GPMC_AD0.GPMC_AD{i}_PULLUDENABLE
  [8] GPMC_A13_MODESELECT rw — Selects between the Default IO Timing Mode and a Virtual or Manual IO Timing Mode. Refer to the device Data Manual for definition of the required settings for a given mode of operation. When this bit is 0b1, a Virtual IO Timing Mode can be selected via the DELAYMODE field of this register, as described in, Virtual IO Timing Modes. Manual IO Timing Modes are selected via the procedure described in , Manual IO Timing Modes.
    values as CTRL_CORE_PAD_GPMC_AD0.GPMC_AD{i}_MODESELECT
  [7:4] GPMC_A13_DELAYMODE rw — This bit field selects the Virtual Timing Mode used when the MODESELECT bit is set to 0b1. See, Virtual IO Timing Modes for details.
  [3:0] GPMC_A13_MUXMODE rw
    0=GPMC_A13; 1=QSPI1_RTCLK; 4=VIN2A_HSYNC0 VIN1A_HSYNC0; 7=TIMER7; 8=SPI4_CS2; 9=DMA_EVT2; 14=GPIO2_3; 15=DRIVER OFF
0x1478 CTRL_CORE_PAD_GPMC_A14 reset 0x4000F
  [25] GPMC_A14_WAKEUPEVENT ro
    values as CTRL_CORE_PAD_GPMC_AD0.GPMC_AD{i}_WAKEUPEVENT
  [24] GPMC_A14_WAKEUPENABLE rw
    0=DISABLE (Wakeup is disabled); 1=ENABLE (Wakeup is enabled)
  [19] GPMC_A14_SLEWCONTROL rw
    values as CTRL_CORE_PAD_GPMC_AD0.GPMC_AD{i}_SLEWCONTROL
  [18] GPMC_A14_INPUTENABLE rw
    values as CTRL_CORE_PAD_GPMC_AD0.GPMC_AD{i}_INPUTENABLE
  [17] GPMC_A14_PULLTYPESELECT rw
    values as CTRL_CORE_PAD_GPMC_AD0.GPMC_AD{i}_PULLTYPESELECT
  [16] GPMC_A14_PULLUDENABLE rw
    values as CTRL_CORE_PAD_GPMC_AD0.GPMC_AD{i}_PULLUDENABLE
  [8] GPMC_A14_MODESELECT rw — Selects between the Default IO Timing Mode and a Virtual or Manual IO Timing Mode. Refer to the device Data Manual for definition of the required settings for a given mode of operation. When this bit is 0b1, a Virtual IO Timing Mode can be selected via the DELAYMODE field of this register, as described in, Virtual IO Timing Modes. Manual IO Timing Modes are selected via the procedure described in , Manual IO Timing Modes.
    values as CTRL_CORE_PAD_GPMC_AD0.GPMC_AD{i}_MODESELECT
  [7:4] GPMC_A14_DELAYMODE rw — This bit field selects the Virtual Timing Mode used when the MODESELECT bit is set to 0b1. See, Virtual IO Timing Modes for details.
  [3:0] GPMC_A14_MUXMODE rw
    0=GPMC_A14; 1=QSPI1_D3; 4=VIN2A_VSYNC0 VIN1A_VSYNC0; 7=TIMER6; 8=SPI4_CS3; 14=GPIO2_4; 15=DRIVER OFF
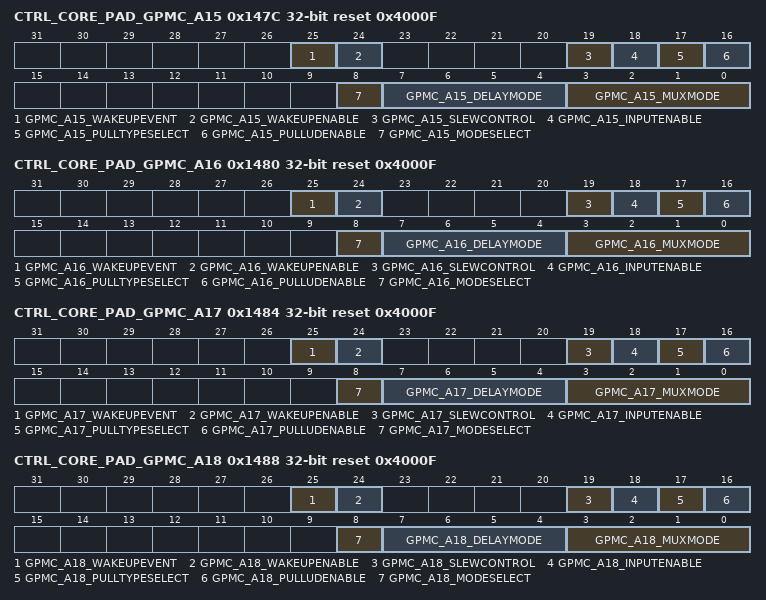
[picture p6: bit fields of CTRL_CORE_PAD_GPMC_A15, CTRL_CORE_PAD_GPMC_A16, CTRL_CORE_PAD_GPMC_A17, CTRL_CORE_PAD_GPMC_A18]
0x147C CTRL_CORE_PAD_GPMC_A15 reset 0x4000F
  [25] GPMC_A15_WAKEUPEVENT ro
    values as CTRL_CORE_PAD_GPMC_AD0.GPMC_AD{i}_WAKEUPEVENT
  [24] GPMC_A15_WAKEUPENABLE rw
    0=DISABLE (Wakeup is disabled); 1=ENABLE (Wakeup is enabled)
  [19] GPMC_A15_SLEWCONTROL rw
    values as CTRL_CORE_PAD_GPMC_AD0.GPMC_AD{i}_SLEWCONTROL
  [18] GPMC_A15_INPUTENABLE rw
    values as CTRL_CORE_PAD_GPMC_AD0.GPMC_AD{i}_INPUTENABLE
  [17] GPMC_A15_PULLTYPESELECT rw
    values as CTRL_CORE_PAD_GPMC_AD0.GPMC_AD{i}_PULLTYPESELECT
  [16] GPMC_A15_PULLUDENABLE rw
    values as CTRL_CORE_PAD_GPMC_AD0.GPMC_AD{i}_PULLUDENABLE
  [8] GPMC_A15_MODESELECT rw — Selects between the Default IO Timing Mode and a Virtual or Manual IO Timing Mode. Refer to the device Data Manual for definition of the required settings for a given mode of operation. When this bit is 0b1, a Virtual IO Timing Mode can be selected via the DELAYMODE field of this register, as described in, Virtual IO Timing Modes. Manual IO Timing Modes are selected via the procedure described in , Manual IO Timing Modes.
    values as CTRL_CORE_PAD_GPMC_AD0.GPMC_AD{i}_MODESELECT
  [7:4] GPMC_A15_DELAYMODE rw — This bit field selects the Virtual Timing Mode used when the MODESELECT bit is set to 0b1. See, Virtual IO Timing Modes for details.
  [3:0] GPMC_A15_MUXMODE rw
    0=GPMC_A15; 1=QSPI1_D2; 4=VIN2A_D8 VIN1A_D8; 7=TIMER5; 14=GPIO2_5; 15=DRIVER OFF
0x1480 CTRL_CORE_PAD_GPMC_A16 reset 0x4000F
  [25] GPMC_A16_WAKEUPEVENT ro
    values as CTRL_CORE_PAD_GPMC_AD0.GPMC_AD{i}_WAKEUPEVENT
  [24] GPMC_A16_WAKEUPENABLE rw
    0=DISABLE (Wakeup is disabled); 1=ENABLE (Wakeup is enabled)
  [19] GPMC_A16_SLEWCONTROL rw
    values as CTRL_CORE_PAD_GPMC_AD0.GPMC_AD{i}_SLEWCONTROL
  [18] GPMC_A16_INPUTENABLE rw
    values as CTRL_CORE_PAD_GPMC_AD0.GPMC_AD{i}_INPUTENABLE
  [17] GPMC_A16_PULLTYPESELECT rw
    values as CTRL_CORE_PAD_GPMC_AD0.GPMC_AD{i}_PULLTYPESELECT
  [16] GPMC_A16_PULLUDENABLE rw
    values as CTRL_CORE_PAD_GPMC_AD0.GPMC_AD{i}_PULLUDENABLE
  [8] GPMC_A16_MODESELECT rw — Selects between the Default IO Timing Mode and a Virtual or Manual IO Timing Mode. Refer to the device Data Manual for definition of the required settings for a given mode of operation. When this bit is 0b1, a Virtual IO Timing Mode can be selected via the DELAYMODE field of this register, as described in, Virtual IO Timing Modes. Manual IO Timing Modes are selected via the procedure described in , Manual IO Timing Modes.
    values as CTRL_CORE_PAD_GPMC_AD0.GPMC_AD{i}_MODESELECT
  [7:4] GPMC_A16_DELAYMODE rw — This bit field selects the Virtual Timing Mode used when the MODESELECT bit is set to 0b1. See, Virtual IO Timing Modes for details.
  [3:0] GPMC_A16_MUXMODE rw
    0=GPMC_A16; 1=QSPI1_D0; 4=VIN2A_D9 VIN1A_D9; 14=GPIO2_6; 15=DRIVER OFF
0x1484 CTRL_CORE_PAD_GPMC_A17 reset 0x4000F
  [25] GPMC_A17_WAKEUPEVENT ro
    values as CTRL_CORE_PAD_GPMC_AD0.GPMC_AD{i}_WAKEUPEVENT
  [24] GPMC_A17_WAKEUPENABLE rw
    0=DISABLE (Wakeup is disabled); 1=ENABLE (Wakeup is enabled)
  [19] GPMC_A17_SLEWCONTROL rw
    values as CTRL_CORE_PAD_GPMC_AD0.GPMC_AD{i}_SLEWCONTROL
  [18] GPMC_A17_INPUTENABLE rw
    values as CTRL_CORE_PAD_GPMC_AD0.GPMC_AD{i}_INPUTENABLE
  [17] GPMC_A17_PULLTYPESELECT rw
    values as CTRL_CORE_PAD_GPMC_AD0.GPMC_AD{i}_PULLTYPESELECT
  [16] GPMC_A17_PULLUDENABLE rw
    values as CTRL_CORE_PAD_GPMC_AD0.GPMC_AD{i}_PULLUDENABLE
  [8] GPMC_A17_MODESELECT rw — Selects between the Default IO Timing Mode and a Virtual or Manual IO Timing Mode. Refer to the device Data Manual for definition of the required settings for a given mode of operation. When this bit is 0b1, a Virtual IO Timing Mode can be selected via the DELAYMODE field of this register, as described in, Virtual IO Timing Modes. Manual IO Timing Modes are selected via the procedure described in , Manual IO Timing Modes.
    values as CTRL_CORE_PAD_GPMC_AD0.GPMC_AD{i}_MODESELECT
  [7:4] GPMC_A17_DELAYMODE rw — This bit field selects the Virtual Timing Mode used when the MODESELECT bit is set to 0b1. See, Virtual IO Timing Modes for details.
  [3:0] GPMC_A17_MUXMODE rw
    0=GPMC_A17; 1=QSPI1_D1; 4=VIN2A_D10 VIN1A_D10; 14=GPIO2_7; 15=DRIVER OFF
0x1488 CTRL_CORE_PAD_GPMC_A18 reset 0x4000F
  [25] GPMC_A18_WAKEUPEVENT ro
    values as CTRL_CORE_PAD_GPMC_AD0.GPMC_AD{i}_WAKEUPEVENT
  [24] GPMC_A18_WAKEUPENABLE rw
    0=DISABLE (Wakeup is disabled); 1=ENABLE (Wakeup is enabled)
  [19] GPMC_A18_SLEWCONTROL rw
    values as CTRL_CORE_PAD_GPMC_AD0.GPMC_AD{i}_SLEWCONTROL
  [18] GPMC_A18_INPUTENABLE rw
    values as CTRL_CORE_PAD_GPMC_AD0.GPMC_AD{i}_INPUTENABLE
  [17] GPMC_A18_PULLTYPESELECT rw
    values as CTRL_CORE_PAD_GPMC_AD0.GPMC_AD{i}_PULLTYPESELECT
  [16] GPMC_A18_PULLUDENABLE rw
    values as CTRL_CORE_PAD_GPMC_AD0.GPMC_AD{i}_PULLUDENABLE
  [8] GPMC_A18_MODESELECT rw — Selects between the Default IO Timing Mode and a Virtual or Manual IO Timing Mode. Refer to the device Data Manual for definition of the required settings for a given mode of operation. When this bit is 0b1, a Virtual IO Timing Mode can be selected via the DELAYMODE field of this register, as described in, Virtual IO Timing Modes. Manual IO Timing Modes are selected via the procedure described in , Manual IO Timing Modes.
    values as CTRL_CORE_PAD_GPMC_AD0.GPMC_AD{i}_MODESELECT
  [7:4] GPMC_A18_DELAYMODE rw — This bit field selects the Virtual Timing Mode used when the MODESELECT bit is set to 0b1. See, Virtual IO Timing Modes for details.
  [3:0] GPMC_A18_MUXMODE rw
    0=GPMC_A18; 1=QSPI1_SCLK; 4=VIN2A_D11 VIN1A_D11; 14=GPIO2_8; 15=DRIVER OFF
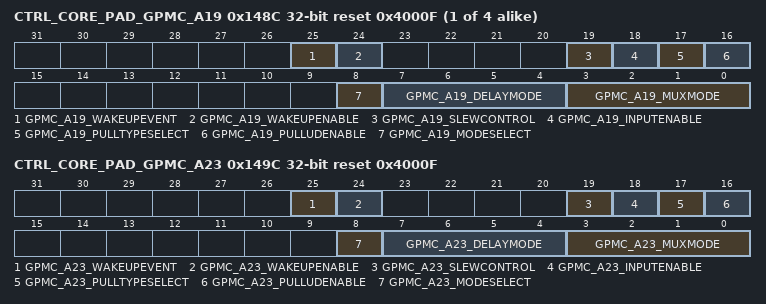
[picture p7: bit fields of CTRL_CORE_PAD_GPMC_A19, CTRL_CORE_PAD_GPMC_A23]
{0x1440+4i} CTRL_CORE_PAD_GPMC_A{i} reset 0x4000F (i=19..22)
  [25] GPMC_A{i}_WAKEUPEVENT ro
    values as CTRL_CORE_PAD_GPMC_AD0.GPMC_AD{i}_WAKEUPEVENT
  [24] GPMC_A{i}_WAKEUPENABLE rw
    0=DISABLE (Wakeup is disabled); 1=ENABLE (Wakeup is enabled)
  [19] GPMC_A{i}_SLEWCONTROL rw
    values as CTRL_CORE_PAD_GPMC_AD0.GPMC_AD{i}_SLEWCONTROL
  [18] GPMC_A{i}_INPUTENABLE rw
    values as CTRL_CORE_PAD_GPMC_AD0.GPMC_AD{i}_INPUTENABLE
  [17] GPMC_A{i}_PULLTYPESELECT rw
    values as CTRL_CORE_PAD_GPMC_AD0.GPMC_AD{i}_PULLTYPESELECT
  [16] GPMC_A{i}_PULLUDENABLE rw
    values as CTRL_CORE_PAD_GPMC_AD0.GPMC_AD{i}_PULLUDENABLE
  [8] GPMC_A{i}_MODESELECT rw — Selects between the Default IO Timing Mode and a Virtual or Manual IO Timing Mode. Refer to the device Data Manual for definition of the required settings for a given mode of operation. When this bit is 0b1, a Virtual IO Timing Mode can be selected via the DELAYMODE field of this register, as described in, Virtual IO Timing Modes. Manual IO Timing Modes are selected via the procedure described in , Manual IO Timing Modes.
    values as CTRL_CORE_PAD_GPMC_AD0.GPMC_AD{i}_MODESELECT
  [7:4] GPMC_A{i}_DELAYMODE rw — This bit field selects the Virtual Timing Mode used when the MODESELECT bit is set to 0b1. See, Virtual IO Timing Modes for details.
  [3:0] GPMC_A{i}_MUXMODE rw
    0=GPMC_A{i}; 1=MMC2_DAT{i-15}; 2=GPMC_A{i-6}; 4=VIN2A_D{i-7} VIN1A_D{i-7}; 6=VIN2B_D{i-19} VIN1B_D{i-19}; 14=GPIO2_{i-10}; 15=DRIVER OFF
0x149C CTRL_CORE_PAD_GPMC_A23 reset 0x4000F
  [25] GPMC_A23_WAKEUPEVENT ro
    values as CTRL_CORE_PAD_GPMC_AD0.GPMC_AD{i}_WAKEUPEVENT
  [24] GPMC_A23_WAKEUPENABLE rw
    0=DISABLE (Wakeup is disabled); 1=ENABLE (Wakeup is enabled)
  [19] GPMC_A23_SLEWCONTROL rw
    values as CTRL_CORE_PAD_GPMC_AD0.GPMC_AD{i}_SLEWCONTROL
  [18] GPMC_A23_INPUTENABLE rw
    values as CTRL_CORE_PAD_GPMC_AD0.GPMC_AD{i}_INPUTENABLE
  [17] GPMC_A23_PULLTYPESELECT rw
    values as CTRL_CORE_PAD_GPMC_AD0.GPMC_AD{i}_PULLTYPESELECT
  [16] GPMC_A23_PULLUDENABLE rw
    values as CTRL_CORE_PAD_GPMC_AD0.GPMC_AD{i}_PULLUDENABLE
  [8] GPMC_A23_MODESELECT rw — Selects between the Default IO Timing Mode and a Virtual or Manual IO Timing Mode. Refer to the device Data Manual for definition of the required settings for a given mode of operation. When this bit is 0b1, a Virtual IO Timing Mode can be selected via the DELAYMODE field of this register, as described in, Virtual IO Timing Modes. Manual IO Timing Modes are selected via the procedure described in , Manual IO Timing Modes.
    values as CTRL_CORE_PAD_GPMC_AD0.GPMC_AD{i}_MODESELECT
  [7:4] GPMC_A23_DELAYMODE rw — This bit field selects the Virtual Timing Mode used when the MODESELECT bit is set to 0b1. See, Virtual IO Timing Modes for details.
  [3:0] GPMC_A23_MUXMODE rw
    0=GPMC_A23; 1=MMC2_CLK; 2=GPMC_A17; 4=VIN2A_FLD0 VIN1A_FLD0; 6=VIN2B_D4 VIN1B_D4; 14=GPIO2_13; 15=DRIVER OFF
